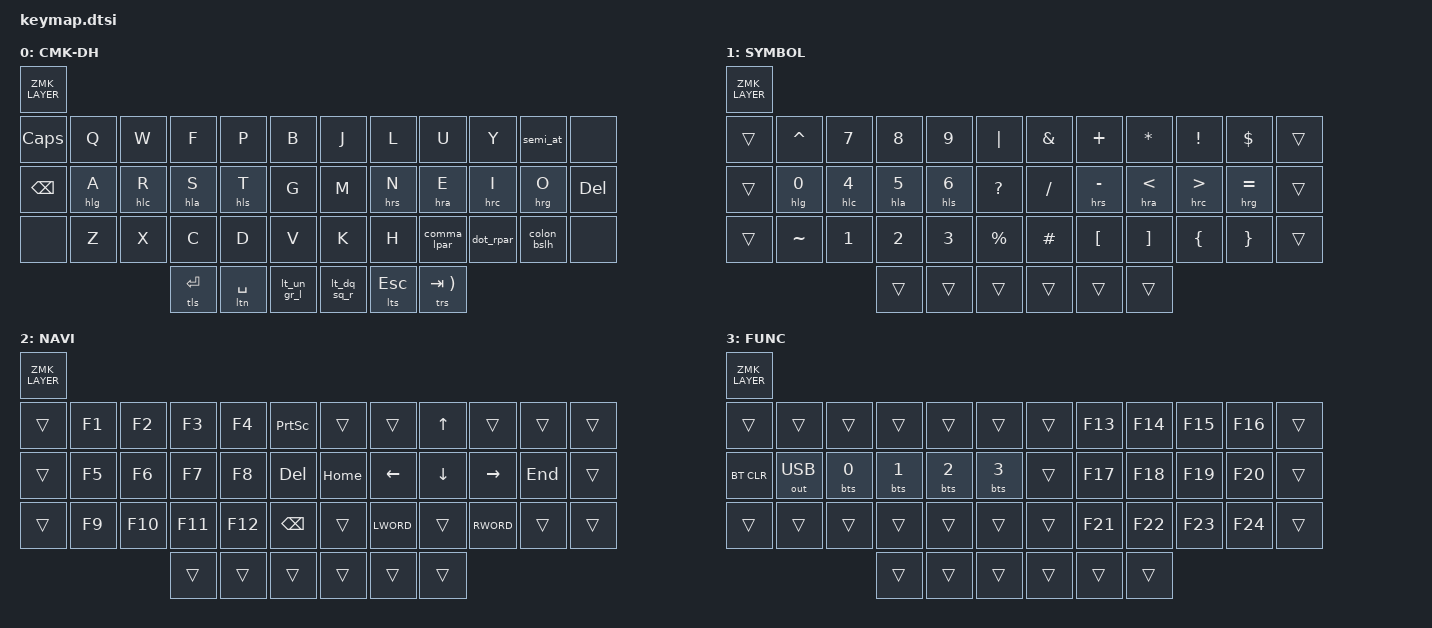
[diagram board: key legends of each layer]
#include <dt-bindings/zmk/keys.h>
#include <dt-bindings/zmk/outputs.h>
#include <dt-bindings/zmk/bt.h>

#define DEF 0
#define SYM 1
#define NAV 2
#define FUN 3

#define XXX  &none
#define ___  &trans

#define hls hlh LSHFT
#define hrs hrh RSHFT
#define hlc hlh LCTRL
#define hrc hrh RCTRL
#define hla hlh LALT
#define hra hrh RALT
#define hlg hl  LGUI
#define hrg hr  RGUI
#define tls mt  LSHFT
#define trs mt  RSHFT
#define lts lth SYM
#define ltn ltt NAV

#define lt_un_gr_l lt_un_gr SYM 0
#define lt_dq_sq_r lt_dq_sq FUN 0

#define LWORD LC(LEFT)
#define RWORD RC(RIGHT)

#include "behaviors.dtsi"
#include "macros.dtsi"
#include "combos.dtsi"

#ifndef ZMK_LAYER
    #define ZMK_LAYER(LT, RT, LM, RM, LB, RB, LH, RH) \
        LT RT LM RM LB RB LH RH
#endif

/ {
    conditional_layers {
        compatible = "zmk,conditional-layers";
        tri_layer {
            if-layers = <SYM NAV>;
            then-layer = <FUN>;
        };
    };

    keymap {
        compatible = "zmk,keymap";
        default_layer {
            display-name = "CMK-DH";
            bindings = <ZMK_LAYER(
//  ╭─────────────┬─────────────┬─────────────┬─────────────┬─────────────┬─────────────╮  ╭─────────────┬─────────────┬─────────────┬─────────────┬─────────────┬─────────────╮
      &kp   CAPS    &kp   Q       &kp   W       &kp   F       &kp   P       &kp   B     ,    &kp   J       &kp   L       &kp   U       &kp   Y       &semi_at      XXX         ,
//  ├─────────────┼─────────────┼─────────────┼─────────────┼─────────────┼─────────────┤  ├─────────────┼─────────────┼─────────────┼─────────────┼─────────────┼─────────────┤
      &kp   BSPC    &hlg  A       &hlc  R       &hla  S       &hls  T       &kp   G     ,    &kp   M       &hrs  N       &hra  E       &hrc  I       &hrg  O       &kp   DEL   ,
//  ├─────────────┼─────────────┼─────────────┼─────────────┼─────────────┼─────────────┤  ├─────────────┼─────────────┼─────────────┼─────────────┼─────────────┼─────────────┤
      XXX           &kp   Z       &kp   X       &kp   C       &kp   D       &kp   V     ,    &kp   K       &kp   H       &comma_lpar   &dot_rpar     &colon_bslh   XXX         ,
//  ╰─────────────┴─────────────┴─────────────┼─────────────┼─────────────┼─────────────┤  ├─────────────┼─────────────┼─────────────┼─────────────┴─────────────┴─────────────╯
                                                &tls  RET     &ltn  SPACE   &lt_un_gr_l ,    &lt_dq_sq_r   &lts ESC      &trs TAB
//                                            ╰─────────────┴─────────────┴─────────────╯  ╰─────────────┴─────────────┴─────────────╯
            )>;
        };
        symbol_layer {
            display-name = "SYMBOL";
            bindings = <ZMK_LAYER(
//  ╭─────────────┬─────────────┬─────────────┬─────────────┬─────────────┬─────────────╮  ╭─────────────┬─────────────┬─────────────┬─────────────┬─────────────┬─────────────╮
      ___           &kp   CARET   &kp   N7      &kp   N8      &kp   N9      &kp   PIPE  ,    &kp   AMPS    &kp   PLUS    &kp   STAR    &kp   EXCL    &kp   DLLR    ___         ,
//  ├─────────────┼─────────────┼─────────────┼─────────────┼─────────────┼─────────────┤  ├─────────────┼─────────────┼─────────────┼─────────────┼─────────────┼─────────────┤
      ___           &hlg  N0      &hlc  N4      &hla  N5      &hls  N6      &kp   QMARK ,    &kp   FSLH    &hrs  MINUS   &hra  LT      &hrc  GT      &hrg  EQUAL   ___         ,
//  ├─────────────┼─────────────┼─────────────┼─────────────┼─────────────┼─────────────┤  ├─────────────┼─────────────┼─────────────┼─────────────┼─────────────┼─────────────┤
      ___           &kp   TILDE   &kp   N1      &kp   N2      &kp   N3      &kp   PRCNT ,    &kp   HASH    &kp   LBKT    &kp   RBKT    &kp   LBRC    &kp   RBRC    ___         ,
//  ╰─────────────┴─────────────┴─────────────┼─────────────┼─────────────┼─────────────┤  ├─────────────┼─────────────┼─────────────┼─────────────┴─────────────┴─────────────╯
                                                ___           ___           ___         ,    ___           ___           ___
//                                            ╰─────────────┴─────────────┴─────────────╯  ╰─────────────┴─────────────┴─────────────╯
            )>;
        };
        navigation_layer {
            display-name = "NAVI";
            bindings = <ZMK_LAYER(
//  ╭─────────────┬─────────────┬─────────────┬─────────────┬─────────────┬─────────────╮  ╭─────────────┬─────────────┬─────────────┬─────────────┬─────────────┬─────────────╮
      ___           &kp   F1      &kp   F2      &kp   F3      &kp   F4      &kp   PSCRN ,    ___           ___           &kp   UP      ___           ___           ___         ,
//  ├─────────────┼─────────────┼─────────────┼─────────────┼─────────────┼─────────────┤  ├─────────────┼─────────────┼─────────────┼─────────────┼─────────────┼─────────────┤
      ___           &kp   F5      &kp   F6      &kp   F7      &kp   F8      &kp   DEL   ,    &kp   HOME    &kp   LEFT    &kp   DOWN    &kp   RIGHT   &kp   END     ___         ,
//  ├─────────────┼─────────────┼─────────────┼─────────────┼─────────────┼─────────────┤  ├─────────────┼─────────────┼─────────────┼─────────────┼─────────────┼─────────────┤
      ___           &kp   F9      &kp   F10     &kp   F11     &kp   F12     &kp   BSPC  ,    ___           &kp   LWORD   ___           &kp   RWORD   ___           ___         ,
//  ╰─────────────┴─────────────┴─────────────┼─────────────┼─────────────┼─────────────┤  ├─────────────┼─────────────┼─────────────┼─────────────┴─────────────┴─────────────╯
                                                ___           ___           ___         ,    ___           ___           ___
//                                            ╰─────────────┴─────────────┴─────────────╯  ╰─────────────┴─────────────┴─────────────╯
            )>;
        };
        function_layer {
            display-name = "FUNC";
            bindings = <ZMK_LAYER(
//  ╭─────────────┬─────────────┬─────────────┬─────────────┬─────────────┬─────────────╮  ╭─────────────┬─────────────┬─────────────┬─────────────┬─────────────┬─────────────╮
      ___           ___           ___           ___           ___           ___         ,    ___           &kp   F13     &kp   F14     &kp   F15     &kp   F16     ___         ,
//  ├─────────────┼─────────────┼─────────────┼─────────────┼─────────────┼─────────────┤  ├─────────────┼─────────────┼─────────────┼─────────────┼─────────────┼─────────────┤
      &bt BT_CLR    &out OUT_USB  &bts 0        &bts 1        &bts 2        &bts 3      ,    ___           &kp   F17     &kp   F18     &kp   F19     &kp   F20     ___         ,
//  ├─────────────┼─────────────┼─────────────┼─────────────┼─────────────┼─────────────┤  ├─────────────┼─────────────┼─────────────┼─────────────┼─────────────┼─────────────┤
      ___           ___           ___           ___           ___           ___         ,    ___           &kp   F21     &kp   F22     &kp   F23     &kp   F24     ___         ,
//  ╰─────────────┴─────────────┴─────────────┼─────────────┼─────────────┼─────────────┤  ├─────────────┼─────────────┼─────────────┼─────────────┴─────────────┴─────────────╯
                                                ___           ___           ___         ,    ___           ___           ___
//                                            ╰─────────────┴─────────────┴─────────────╯  ╰─────────────┴─────────────┴─────────────╯
            )>;
        };
    };
};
